# MAIN_SEC_MMR_MAIN_SEC_MMR_CFG2_45900000h register map
Vendor: Texas Instruments
Peripheral module from a debugger description file (folder am62L).
Registers are 32-bit, access per field, reset 0xAA unless marked. A register's access mark holds for its fields unless they carry their own. Offsets are as the file gives them; lines under a group give offsets from that group; [hi:lo] are bit positions; {n}, {i} and the like mark numbered series; 'fields as' and 'values as' point back to an identical list; <NAME> marks a mode.

## MAIN_SEC_MMR_CFG2
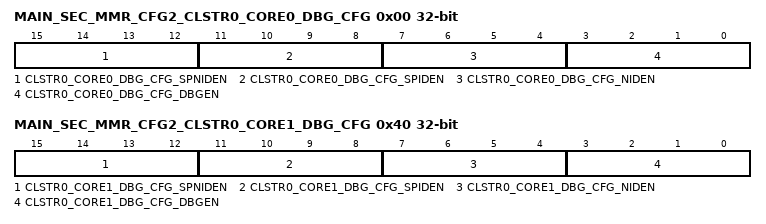
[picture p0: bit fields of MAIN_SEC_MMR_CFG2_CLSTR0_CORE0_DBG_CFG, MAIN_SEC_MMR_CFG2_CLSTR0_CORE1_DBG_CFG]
0x00 MAIN_SEC_MMR_CFG2_CLSTR0_CORE0_DBG_CFG — Debug Enable for Core0 of Cluster0
  [15:12] CLSTR0_CORE0_DBG_CFG_SPNIDEN ro — Cluster0 Core0 Secure Non-Invasive debug activate.This is a fault tolerant bitfield that must be set 4'hA to activate4'b1010 - Activatedothers - Deactivated Field values (others are reserved):4'b1010 - Secure Non-Invasive Debug is Active Reset Source: sys_por_rst_n
  [11:8] CLSTR0_CORE0_DBG_CFG_SPIDEN ro — Cluster0 Core0 Secure Invasive debug activate.This is a fault tolerant bitfield that must be set 4'hA to activate4'b1010 - Activatedothers - Deactivated Field values (others are reserved):4'b1010 - Secure Invasive Debug is Active Reset Source: sys_por_rst_n
  [7:4] CLSTR0_CORE0_DBG_CFG_NIDEN rw — Cluster0 Core0 Non-Invasive debug activate.This is a fault tolerant bitfield that must be set 4'hA to activate4'b1010 - Activatedothers - Deactivated Field values (others are reserved):4'b1010 - Non-Invasive Debug is Active Reset Source: sys_por_rst_n
  [3:0] CLSTR0_CORE0_DBG_CFG_DBGEN rw — Cluster0 Core0 Invasive debug activate.This is a fault tolerant bitfield that must be set 4'hA to activate4'b1010 - Activatedothers - Deactivated Field values (others are reserved):4'b1010 - Invasive Debug is Active Reset Source: sys_por_rst_n
0x40 MAIN_SEC_MMR_CFG2_CLSTR0_CORE1_DBG_CFG — Debug Enable for Core1 of Cluster0
  [15:12] CLSTR0_CORE1_DBG_CFG_SPNIDEN ro — Cluster0 Core1 Secure Non-Invasive debug activate.This is a fault tolerant bitfield that must be set 4'hA to activate4'b1010 - Activatedothers - Deactivated Field values (others are reserved):4'b1010 - Secure Non-Invasive Debug is Active Reset Source: sys_por_rst_n
  [11:8] CLSTR0_CORE1_DBG_CFG_SPIDEN ro — Cluster0 Core1 Secure Invasive debug activate.This is a fault tolerant bitfield that must be set 4'hA to activate4'b1010 - Activatedothers - Deactivated Field values (others are reserved):4'b1010 - Secure Invasive Debug is Active Reset Source: sys_por_rst_n
  [7:4] CLSTR0_CORE1_DBG_CFG_NIDEN rw — Cluster0 Core1 Non-Invasive debug activate.This is a fault tolerant bitfield that must be set 4'hA to activate4'b1010 - Activatedothers - Deactivated Field values (others are reserved):4'b1010 - Non-Invasive Debug is Active Reset Source: sys_por_rst_n
  [3:0] CLSTR0_CORE1_DBG_CFG_DBGEN rw — Cluster0 Core1 Invasive debug activate.This is a fault tolerant bitfield that must be set 4'hA to activate4'b1010 - Activatedothers - Deactivated Field values (others are reserved):4'b1010 - Invasive Debug is Active Reset Source: sys_por_rst_n
